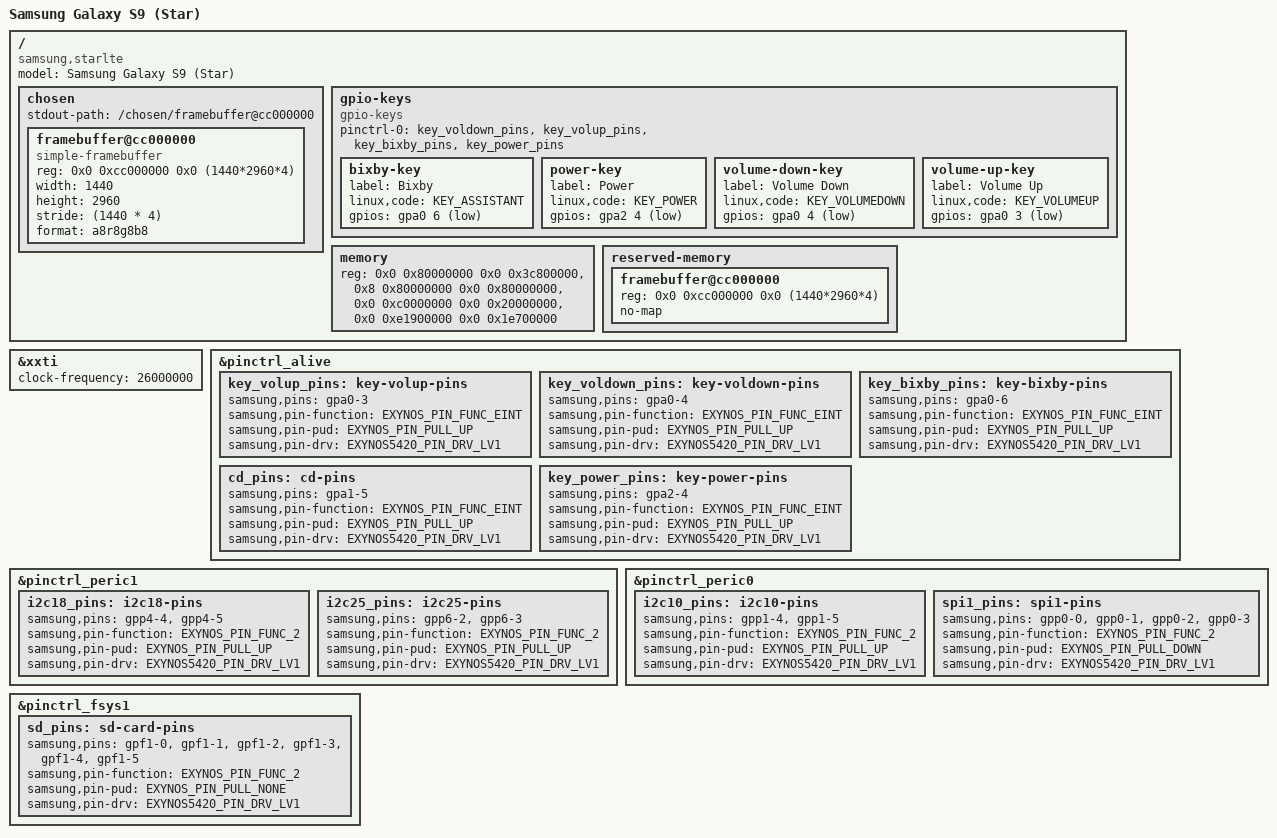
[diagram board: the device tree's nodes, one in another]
// SPDX-License-Identifier: GPL-2.0
/*
 * Samsung Exynos9810 SoC device tree source
 *
 * Samsung Exynos9810 SoC device nodes are listed in this file.
 * Exynos9810 based board files can include this file and provide
 * values for board specific bindings.
 */

/dts-v1/;

#include "exynos9810.dtsi"
#include <dt-bindings/gpio/gpio.h>
#include <dt-bindings/input/input.h>

/ {
	model = "Samsung Galaxy S9 (Star)";
	compatible = "samsung,starlte", "samsung,exynos9810";

	#address-cells = <2>;
	#size-cells = <2>;

	chosen {
		#address-cells = <2>;
		#size-cells = <2>;
		ranges;

		stdout-path = "/chosen/framebuffer@cc000000";

		framebuffer@cc000000 {
			compatible = "simple-framebuffer";
			reg = <0x0 0xcc000000 0x0 (1440*2960*4)>;
			width = <1440>;
			height = <2960>;
			stride = <(1440 * 4)>;
			format = "a8r8g8b8";
		};
	};

	gpio-keys {
		compatible = "gpio-keys";
		pinctrl-names = "default";
		pinctrl-0 = <&key_voldown_pins &key_volup_pins &key_bixby_pins &key_power_pins>;

		bixby-key {
			label = "Bixby";
			linux,code = <KEY_ASSISTANT>;
			gpios = <&gpa0 6 GPIO_ACTIVE_LOW>;
		};

		power-key {
			label = "Power";
			linux,code = <KEY_POWER>;
			gpios = <&gpa2 4 GPIO_ACTIVE_LOW>;
		};

		volume-down-key {
			label = "Volume Down";
			linux,code = <KEY_VOLUMEDOWN>;
			gpios = <&gpa0 4 GPIO_ACTIVE_LOW>;
		};

		volume-up-key {
			label = "Volume Up";
			linux,code = <KEY_VOLUMEUP>;
			gpios = <&gpa0 3 GPIO_ACTIVE_LOW>;
		};
	};

	memory {
		device_type = "memory";
		reg = <0x0 0x80000000 0x0 0x3c800000>,
		       <0x8 0x80000000 0x0 0x80000000>,
		       <0x0 0xc0000000 0x0 0x20000000>,
		       <0x0 0xe1900000 0x0 0x1e700000>;
	};

	reserved-memory {
		#address-cells = <2>;
		#size-cells = <2>;
		ranges;
		framebuffer@cc000000 {
			reg = <0x0 0xcc000000 0x0 (1440*2960*4)>;
			no-map;
		};
	};
};

&xxti {
	clock-frequency = <26000000>;
};

&pinctrl_alive {
	key_volup_pins: key-volup-pins {
		samsung,pins = "gpa0-3";
		samsung,pin-function = <EXYNOS_PIN_FUNC_EINT>;
		samsung,pin-pud = <EXYNOS_PIN_PULL_UP>;
		samsung,pin-drv = <EXYNOS5420_PIN_DRV_LV1>;
	};

	key_voldown_pins: key-voldown-pins {
		samsung,pins = "gpa0-4";
		samsung,pin-function = <EXYNOS_PIN_FUNC_EINT>;
		samsung,pin-pud = <EXYNOS_PIN_PULL_UP>;
		samsung,pin-drv = <EXYNOS5420_PIN_DRV_LV1>;
	};

	key_bixby_pins: key-bixby-pins {
		samsung,pins = "gpa0-6";
		samsung,pin-function = <EXYNOS_PIN_FUNC_EINT>;
		samsung,pin-pud = <EXYNOS_PIN_PULL_UP>;
		samsung,pin-drv = <EXYNOS5420_PIN_DRV_LV1>;
	};

	cd_pins: cd-pins {
		samsung,pins = "gpa1-5";
		samsung,pin-function = <EXYNOS_PIN_FUNC_EINT>;
		samsung,pin-pud = <EXYNOS_PIN_PULL_UP>;
		samsung,pin-drv = <EXYNOS5420_PIN_DRV_LV1>;
	};

	key_power_pins: key-power-pins {
		samsung,pins = "gpa2-4";
		samsung,pin-function = <EXYNOS_PIN_FUNC_EINT>;
		samsung,pin-pud = <EXYNOS_PIN_PULL_UP>;
		samsung,pin-drv = <EXYNOS5420_PIN_DRV_LV1>;
	};
};

&pinctrl_peric1 {
	i2c18_pins: i2c18-pins {
		samsung,pins = "gpp4-4", "gpp4-5";
		samsung,pin-function = <EXYNOS_PIN_FUNC_2>;
		samsung,pin-pud = <EXYNOS_PIN_PULL_UP>;
		samsung,pin-drv = <EXYNOS5420_PIN_DRV_LV1>;
	};

	i2c25_pins: i2c25-pins {
		samsung,pins = "gpp6-2", "gpp6-3";
		samsung,pin-function = <EXYNOS_PIN_FUNC_2>;
		samsung,pin-pud = <EXYNOS_PIN_PULL_UP>;
		samsung,pin-drv = <EXYNOS5420_PIN_DRV_LV1>;
	};
};

&pinctrl_peric0 {
	i2c10_pins: i2c10-pins {
		samsung,pins = "gpp1-4", "gpp1-5";
		samsung,pin-function = <EXYNOS_PIN_FUNC_2>;
		samsung,pin-pud = <EXYNOS_PIN_PULL_UP>;
		samsung,pin-drv = <EXYNOS5420_PIN_DRV_LV1>;
	};

	spi1_pins: spi1-pins {
		samsung,pins = "gpp0-0", "gpp0-1", "gpp0-2", "gpp0-3";
		samsung,pin-function = <EXYNOS_PIN_FUNC_2>;
		samsung,pin-pud = <EXYNOS_PIN_PULL_DOWN>;
		samsung,pin-drv = <EXYNOS5420_PIN_DRV_LV1>;
	};
};

&pinctrl_fsys1 {
	sd_pins: sd-card-pins {
		samsung,pins = "gpf1-0", "gpf1-1", "gpf1-2", "gpf1-3", "gpf1-4", "gpf1-5";
		samsung,pin-function = <EXYNOS_PIN_FUNC_2>;
		samsung,pin-pud = <EXYNOS_PIN_PULL_NONE>;
		samsung,pin-drv = <EXYNOS5420_PIN_DRV_LV1>;
	};
};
